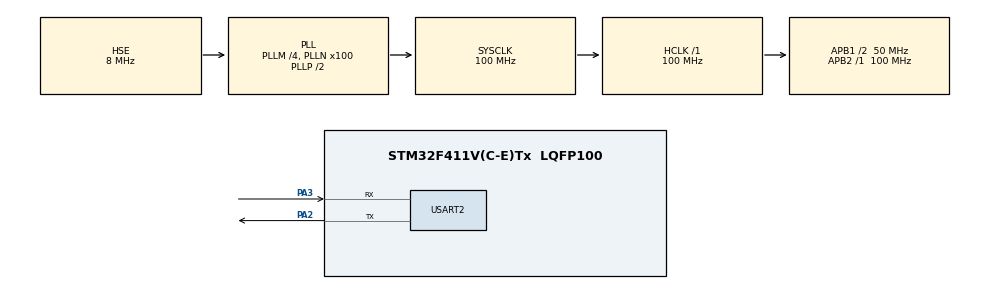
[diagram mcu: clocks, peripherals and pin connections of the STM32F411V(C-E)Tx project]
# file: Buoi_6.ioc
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Mcu.Family=STM32F4
Mcu.Name=STM32F411V(C-E)Tx
Mcu.Package=LQFP100
NVIC.PriorityGroup=NVIC_PRIORITYGROUP_4
NVIC.USART2_IRQn=true\:0\:0\:false\:false\:true\:true\:true\:true
PA13.Mode=Serial_Wire
PA13.Signal=SYS_JTMS-SWDIO
PA14.Mode=Serial_Wire
PA14.Signal=SYS_JTCK-SWCLK
PA2.Mode=Asynchronous
PA2.Signal=USART2_TX
PA3.Mode=Asynchronous
PA3.Signal=USART2_RX
PH0\ -\ OSC_IN.Mode=HSE-External-Oscillator
PH0\ -\ OSC_IN.Signal=RCC_OSC_IN
PH1\ -\ OSC_OUT.Mode=HSE-External-Oscillator
PH1\ -\ OSC_OUT.Signal=RCC_OSC_OUT
ProjectManager.HeapSize=0x200
ProjectManager.StackSize=0x400
ProjectManager.TargetToolchain=MDK-ARM V5.32
RCC.48MHZClocksFreq_Value=50000000
RCC.AHBFreq_Value=100000000
RCC.APB1CLKDivider=RCC_HCLK_DIV2
RCC.APB1Freq_Value=50000000
RCC.APB1TimFreq_Value=100000000
RCC.APB2Freq_Value=100000000
RCC.APB2TimFreq_Value=100000000
RCC.CortexFreq_Value=100000000
RCC.HCLKFreq_Value=100000000
RCC.HSE_VALUE=8000000
RCC.HSI_VALUE=16000000
RCC.LSE_VALUE=32768
RCC.PLLM=4
RCC.PLLN=100
RCC.PLLSourceVirtual=RCC_PLLSOURCE_HSE
RCC.SYSCLKFreq_VALUE=100000000
RCC.SYSCLKSource=RCC_SYSCLKSOURCE_PLLCLK
RCC.VCOOutputFreq_Value=200000000
USART2.VirtualMode=VM_ASYNC
board=custom

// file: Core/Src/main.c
#include "main.h"
#include "usart.h"
#include "gpio.h"

/* USER CODE BEGIN Includes */
#include <string.h>
#include <stdio.h>
/*MA SO DE TEST
189 33 204 129 76 201 44 98 143 21 90 67 85 p
*/
typedef enum bool{false,true}bool;
uint8_t receive;
char arr_receive[100];
bool en_write_arr=false ;
bool done_frame=false;
char count=0;
int mangSo[100];
int soluongso=0;
int dodai=0;
bool flag=false;
int sohientai=0;
char hienthi[10];
/* USER CODE END Includes */

void SystemClock_Config(void);

/* USER CODE BEGIN 0 */

void send_uart (char*string){
	uint8_t len = strlen(string);
	HAL_UART_Transmit(&huart2,(uint8_t *)string,len,2000);
}

void HAL_UART_RxCpltCallback(UART_HandleTypeDef *huart)
{
 if(huart ->Instance ==huart2.Instance )
 {
	 if(en_write_arr == false ){
		 en_write_arr=true ;
		 done_frame=false;
 }
 if(en_write_arr==true){
	arr_receive[count]=receive;
	 if(arr_receive[count]>= '0' &&arr_receive[count]<='9') {
		 sohientai=sohientai *10 + (arr_receive[count]-48);
	 }
	if(arr_receive[count] == ' '){
		mangSo[soluongso++]=sohientai ;
		sohientai =0;
		dodai++;
	}
		for (int i = 0; i < dodai - 1; i++) {
      for (int j = 0; j <dodai - i - 1; j++) {
        if ((mangSo[j] > mangSo[j + 1]) ) {
          int temp = mangSo[j];
          mangSo[j] = mangSo[j + 1];
          mangSo[j + 1] = temp;
        }
      }
    }
		 count++;
 }
 if(receive=='p' && en_write_arr == true){
	 en_write_arr =false;
	 done_frame = true;
	 flag =true;
 }
 HAL_UART_Receive_IT (&huart2 ,&receive ,1);
 }
}
/* USER CODE END 0 */

int main(void)
{

  HAL_Init();

  SystemClock_Config();

  MX_GPIO_Init();
  MX_USART2_UART_Init();
  /* USER CODE BEGIN 2 */
	HAL_UART_Receive_IT (&huart2 ,&receive ,1);
  /* USER CODE END 2 */

  /* USER CODE BEGIN WHILE */
  while (1)
  {
		if(flag ==true){
		 for(int k=0;k<dodai;k++){
			char hienthi2[10];
			sprintf(hienthi2,"\n%d\n",mangSo[k]);
			send_uart(hienthi2);
		 }
		send_uart("Finish\n");
		count=0;
		soluongso=0;
		dodai =0;
		memset(arr_receive,0,100);
		memset(mangSo,0,100);
		flag =false;
	 }

    /* USER CODE END WHILE */

  }
}

void SystemClock_Config(void)
{
  RCC_OscInitTypeDef RCC_OscInitStruct = {0};
  RCC_ClkInitTypeDef RCC_ClkInitStruct = {0};

  __HAL_RCC_PWR_CLK_ENABLE();
  __HAL_PWR_VOLTAGESCALING_CONFIG(PWR_REGULATOR_VOLTAGE_SCALE1);

  RCC_OscInitStruct.OscillatorType = RCC_OSCILLATORTYPE_HSE;
  RCC_OscInitStruct.HSEState = RCC_HSE_ON;
  RCC_OscInitStruct.PLL.PLLState = RCC_PLL_ON;
  RCC_OscInitStruct.PLL.PLLSource = RCC_PLLSOURCE_HSE;
  RCC_OscInitStruct.PLL.PLLM = 4;
  RCC_OscInitStruct.PLL.PLLN = 100;
  RCC_OscInitStruct.PLL.PLLP = RCC_PLLP_DIV2;
  RCC_OscInitStruct.PLL.PLLQ = 4;
  if (HAL_RCC_OscConfig(&RCC_OscInitStruct) != HAL_OK)
  {
    Error_Handler();
  }

  RCC_ClkInitStruct.ClockType = RCC_CLOCKTYPE_HCLK|RCC_CLOCKTYPE_SYSCLK
                              |RCC_CLOCKTYPE_PCLK1|RCC_CLOCKTYPE_PCLK2;
  RCC_ClkInitStruct.SYSCLKSource = RCC_SYSCLKSOURCE_PLLCLK;
  RCC_ClkInitStruct.AHBCLKDivider = RCC_SYSCLK_DIV1;
  RCC_ClkInitStruct.APB1CLKDivider = RCC_HCLK_DIV2;
  RCC_ClkInitStruct.APB2CLKDivider = RCC_HCLK_DIV1;

  if (HAL_RCC_ClockConfig(&RCC_ClkInitStruct, FLASH_LATENCY_3) != HAL_OK)
  {
    Error_Handler();
  }
}

void Error_Handler(void)
{

  __disable_irq();
  while (1)
  {
  }

}
